VERSION ""

NS_ :

BS_: 500

BU_: Vector__XXX

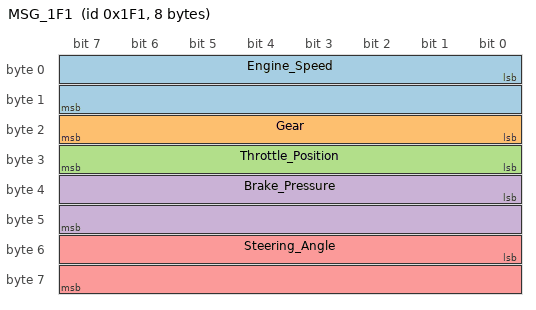
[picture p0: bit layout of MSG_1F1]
BO_ 497 MSG_1F1: 8 Vector__XXX
 SG_ Engine_Speed : 0|16@1+ (1,0) [0|0] "rpm" Vector__XXX
 SG_ Gear : 16|8@1+ (1,0) [0|0] "" Vector__XXX
 SG_ Throttle_Position : 24|8@1+ (0.5,0) [0|127.5] "%" Vector__XXX
 SG_ Brake_Pressure : 32|16@1- (0.01,0) [-327.68|327.67] "bar" Vector__XXX
 SG_ Steering_Angle : 48|16@1- (0.0625,0) [-2048|2047.9375] "��" Vector__XXX

BO_ 498 MSG_1F2: 8 Vector__XXX
 SG_ Yaw_Rate : 48|16@1- (0.01,0) [-327.68|327.67] "��/s" Vector__XXX
